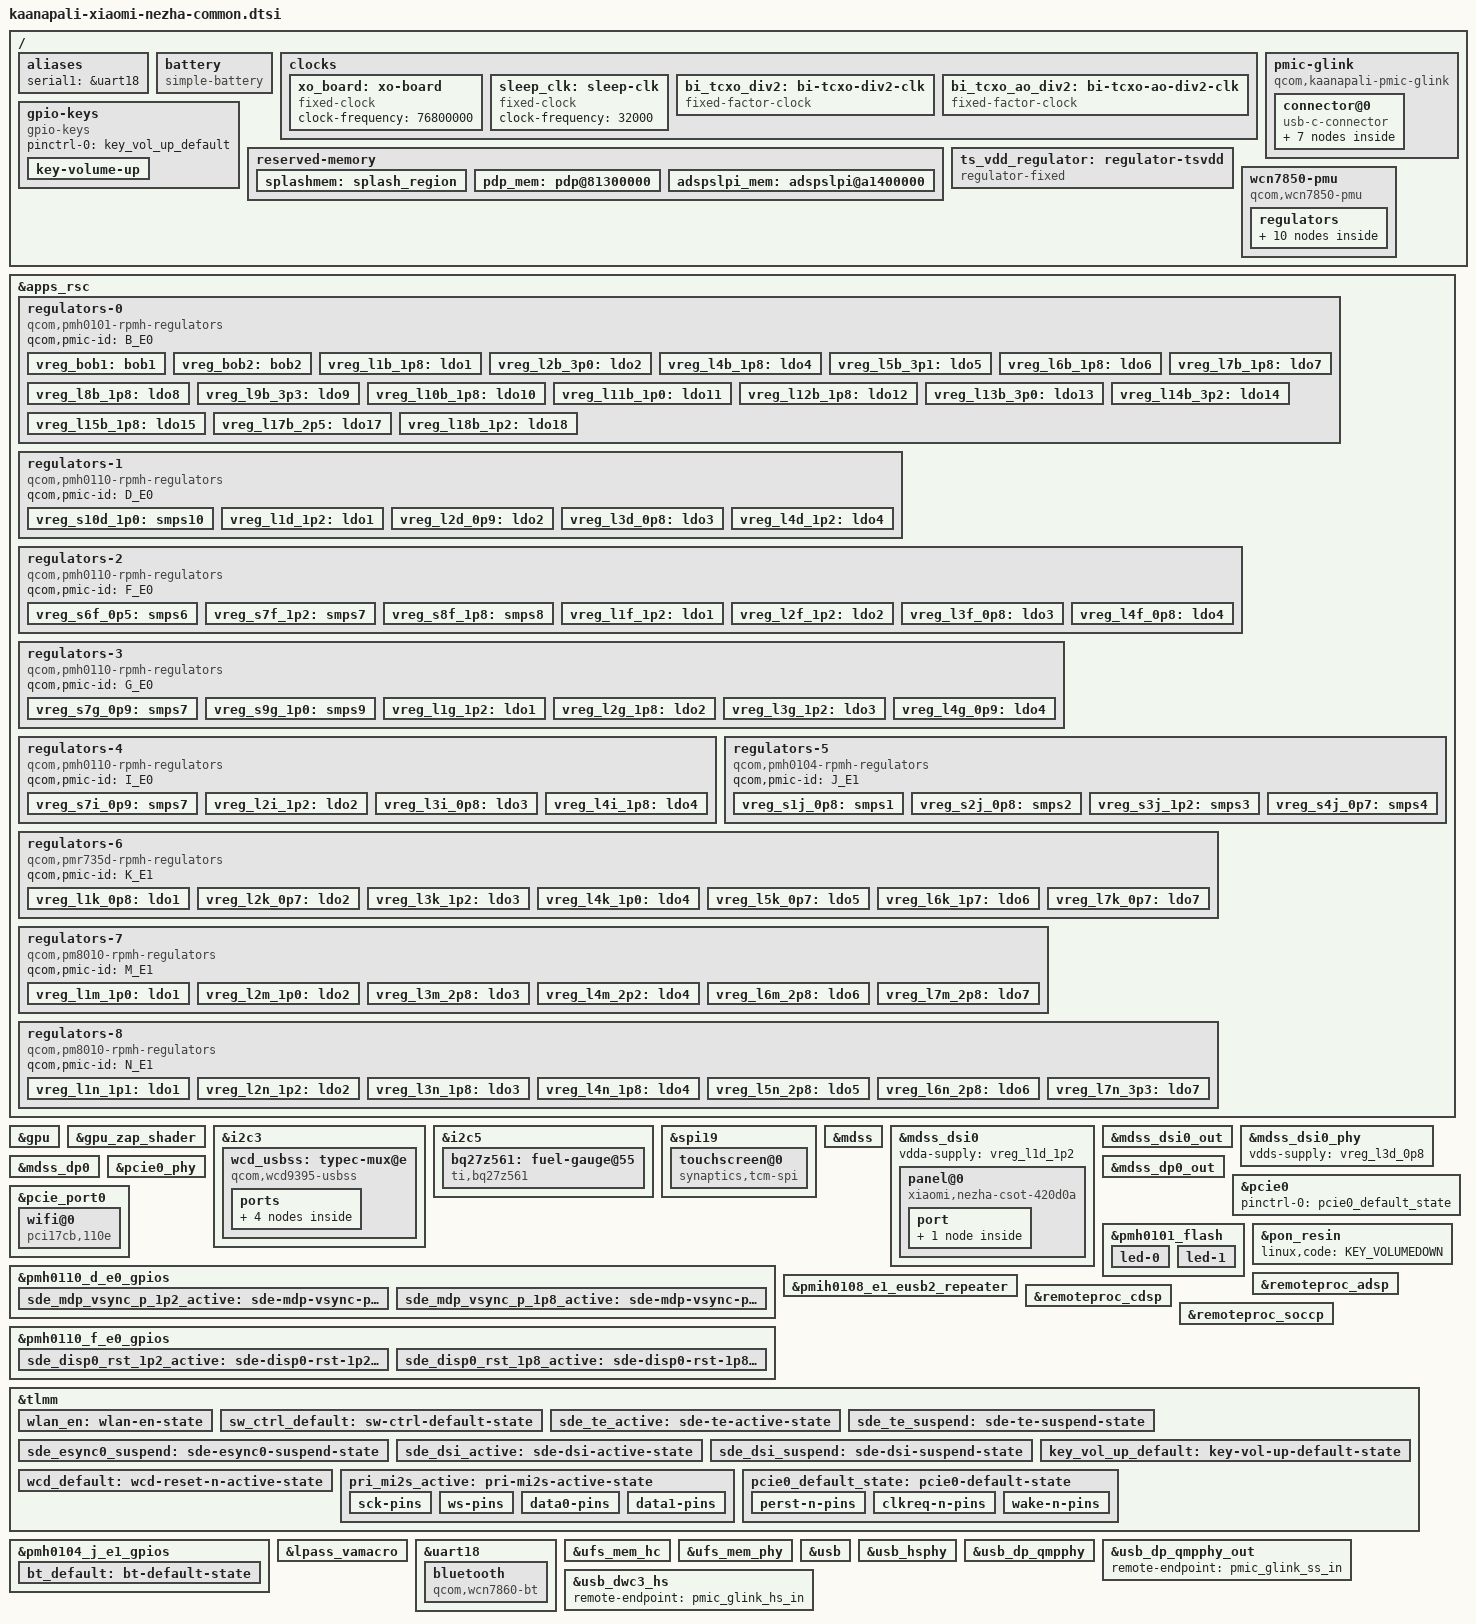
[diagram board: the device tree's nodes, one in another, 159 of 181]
// SPDX-License-Identifier: BSD-3-Clause
/*
 * Copyright (c) Qualcomm Technologies, Inc. and/or its subsidiaries.
 * Copyright (c) Igor Belwon <igor.belwon@mentallysanemainliners.org>
 */

/dts-v1/;

#include <dt-bindings/gpio/gpio.h>
#include <dt-bindings/input/linux-event-codes.h>
#include <dt-bindings/leds/common.h>
#include <dt-bindings/regulator/qcom,rpmh-regulator.h>
#include "kaanapali.dtsi"

#include "pm8010-kaanapali.dtsi"     /* SPMI1: SID-12/13   */
#include "pmd8028-kaanapali.dtsi"    /* SPMI1: SID-4       */
#include "pmh0101.dtsi"              /* SPMI0: SID-1       */
#include "pmh0104-kaanapali.dtsi"    /* SPMI1: SID-9       */
#include "pmh0110-kaanapali.dtsi"    /* SPMI0: SID-3/5/6/8 */
#include "pmih0108-kaanapali.dtsi"   /* SPMI1: SID-7       */
#include "pmk8850.dtsi"              /* SPMI0: SID-0       */
#include "pmr735d-kaanapali.dtsi"    /* SPMI1: SID-10      */

/ {
	aliases {
		serial1 = &uart18;
	};

	battery: battery {
		compatible = "simple-battery";
	};

	clocks {
		xo_board: xo-board {
			compatible = "fixed-clock";
			clock-frequency = <76800000>;
			#clock-cells = <0>;
		};

		sleep_clk: sleep-clk {
			compatible = "fixed-clock";
			clock-frequency = <32000>;
			#clock-cells = <0>;
		};

		bi_tcxo_div2: bi-tcxo-div2-clk {
			compatible = "fixed-factor-clock";
			#clock-cells = <0>;

			clocks = <&rpmhcc RPMH_CXO_CLK>;
			clock-mult = <1>;
			clock-div = <2>;
		};

		bi_tcxo_ao_div2: bi-tcxo-ao-div2-clk {
			compatible = "fixed-factor-clock";
			#clock-cells = <0>;

			clocks = <&rpmhcc RPMH_CXO_CLK_A>;
			clock-mult = <1>;
			clock-div = <2>;
		};
	};

	gpio-keys {
		compatible = "gpio-keys";

		pinctrl-0 = <&key_vol_up_default>;
		pinctrl-names = "default";

		key-volume-up {
			label = "Volume Up";
			linux,code = <KEY_VOLUMEUP>;
			gpios = <&tlmm 101 GPIO_ACTIVE_LOW>;
			debounce-interval = <15>;
			linux,can-disable;
			wakeup-source;
		};
	};

	pmic-glink {
		compatible = "qcom,kaanapali-pmic-glink",
			     "qcom,pmic-glink";
		#address-cells = <1>;
		#size-cells = <0>;

		connector@0 {
			compatible = "usb-c-connector";
			reg = <0>;

			power-role = "dual";
			data-role = "dual";

			ports {
				#address-cells = <1>;
				#size-cells = <0>;

				port@0 {
					reg = <0>;

					pmic_glink_hs_in: endpoint {
						remote-endpoint = <&usb_dwc3_hs>;
					};
				};

				port@1 {
					reg = <1>;

					pmic_glink_ss_in: endpoint {
						remote-endpoint = <&usb_dp_qmpphy_out>;
					};
				};

				port@2 {
					reg = <2>;

					pmic_glink_sbu: endpoint {
						remote-endpoint = <&wcd_usbss_sbu_mux>;
					};
				};
			};
		};
	};

	reserved-memory {
		/*
		 * If we do not have this exact region with this exact name
		 * present, the bootloader disables the display panel and
		 * for some reason it cannot be re-enabled.
		 */
		splashmem: splash_region {
			reg = <0x0 0xfc800000 0x0 0x2b00000>;
			no-map;
		};

		/delete-node/ pdp@81300000;
		pdp_mem: pdp@81300000 {
			reg = <0x0 0x81200000 0x0 0x200000>;
			no-map;
		};

		/delete-node/ adspslpi@a1400000;
		adspslpi_mem: adspslpi@a1400000 {
			reg = <0x0 0xa1400000 0x0 0x5580000>;
			no-map;
		};
	};

	ts_vdd_regulator: regulator-tsvdd {
		compatible = "regulator-fixed";
		regulator-name = "ts_vdd";
		regulator-min-microvolt = <3000000>;
		regulator-max-microvolt = <3000000>;

		gpio = <&tlmm 215 GPIO_ACTIVE_HIGH>;
		enable-active-high;
	};

	wcn7850-pmu {
		compatible = "qcom,wcn7850-pmu";

		pinctrl-0 = <&bt_default>, <&sw_ctrl_default>, <&wlan_en>;
		pinctrl-names = "default";

		bt-enable-gpios = <&pmh0104_j_e1_gpios 5 GPIO_ACTIVE_HIGH>;
		wlan-enable-gpios = <&tlmm 16 GPIO_ACTIVE_HIGH>;

		vdd-supply = <&vreg_s2j_0p8>;
		vddio-supply = <&vreg_l2g_1p8>;
		vddio1p2-supply = <&vreg_l3g_1p2>;
		vddaon-supply = <&vreg_s7g_0p9>;
		vdddig-supply = <&vreg_s1j_0p8>;
		vddrfa1p2-supply = <&vreg_s7f_1p2>;
		vddrfa1p8-supply = <&vreg_s8f_1p8>;

		clocks = <&rpmhcc RPMH_RF_CLK1>;

		regulators {
			vreg_pmu_rfa_cmn: ldo0 {
				regulator-name = "vreg_pmu_rfa_cmn";
			};

			vreg_pmu_aon_0p59: ldo1 {
				regulator-name = "vreg_pmu_aon_0p59";
			};

			vreg_pmu_wlcx_0p8: ldo2 {
				regulator-name = "vreg_pmu_wlcx_0p8";
			};

			vreg_pmu_wlmx_0p85: ldo3 {
				regulator-name = "vreg_pmu_wlmx_0p85";
			};

			vreg_pmu_btcmx_0p85: ldo4 {
				regulator-name = "vreg_pmu_btcmx_0p85";
			};

			vreg_pmu_rfa_0p8: ldo5 {
				regulator-name = "vreg_pmu_rfa_0p8";
			};

			vreg_pmu_rfa_1p2: ldo6 {
				regulator-name = "vreg_pmu_rfa_1p2";
			};

			vreg_pmu_rfa_1p8: ldo7 {
				regulator-name = "vreg_pmu_rfa_1p8";
			};

			vreg_pmu_pcie_0p9: ldo8 {
				regulator-name = "vreg_pmu_pcie_0p9";
			};

			vreg_pmu_pcie_1p8: ldo9 {
				regulator-name = "vreg_pmu_pcie_1p8";
			};
		};
	};
};

&apps_rsc {
	regulators-0 {
		compatible = "qcom,pmh0101-rpmh-regulators";
		qcom,pmic-id = "B_E0";

		vreg_bob1: bob1 {
			regulator-name = "vreg_bob1";
			regulator-min-microvolt = <3008000>;
			regulator-max-microvolt = <4000000>;
			regulator-initial-mode = <RPMH_REGULATOR_MODE_HPM>;
		};

		vreg_bob2: bob2 {
			regulator-name = "vreg_bob2";
			regulator-min-microvolt = <2704000>;
			regulator-max-microvolt = <3552000>;
			regulator-initial-mode = <RPMH_REGULATOR_MODE_HPM>;
		};

		vreg_l1b_1p8: ldo1 {
			regulator-name = "vreg_l1b_1p8";
			regulator-min-microvolt = <1800000>;
			regulator-max-microvolt = <1800000>;
			regulator-initial-mode = <RPMH_REGULATOR_MODE_AUTO>;
			regulator-allow-set-load;
			regulator-allowed-modes = <RPMH_REGULATOR_MODE_LPM
						   RPMH_REGULATOR_MODE_AUTO>;
		};

		vreg_l2b_3p0: ldo2 {
			regulator-name = "vreg_l2b_3p0";
			regulator-min-microvolt = <3008000>;
			regulator-max-microvolt = <3048000>;
			regulator-initial-mode = <RPMH_REGULATOR_MODE_AUTO>;
			regulator-allow-set-load;
			regulator-allowed-modes = <RPMH_REGULATOR_MODE_LPM
						   RPMH_REGULATOR_MODE_AUTO>;
		};

		vreg_l4b_1p8: ldo4 {
			regulator-name = "vreg_l4b_1p8";
			regulator-min-microvolt = <1800000>;
			regulator-max-microvolt = <1800000>;
			regulator-initial-mode = <RPMH_REGULATOR_MODE_AUTO>;
			regulator-allow-set-load;
			regulator-allowed-modes = <RPMH_REGULATOR_MODE_LPM
						   RPMH_REGULATOR_MODE_AUTO>;
		};

		vreg_l5b_3p1: ldo5 {
			regulator-name = "vreg_l5b_3p1";
			regulator-min-microvolt = <3100000>;
			regulator-max-microvolt = <3148000>;
			regulator-initial-mode = <RPMH_REGULATOR_MODE_AUTO>;
			regulator-allow-set-load;
			regulator-allowed-modes = <RPMH_REGULATOR_MODE_LPM
						   RPMH_REGULATOR_MODE_AUTO>;
		};

		vreg_l6b_1p8: ldo6 {
			regulator-name = "vreg_l6b_1p8";
			regulator-min-microvolt = <1800000>;
			regulator-max-microvolt = <3008000>;
			regulator-initial-mode = <RPMH_REGULATOR_MODE_AUTO>;
			regulator-allow-set-load;
			regulator-allowed-modes = <RPMH_REGULATOR_MODE_LPM
						   RPMH_REGULATOR_MODE_AUTO>;
		};

		vreg_l7b_1p8: ldo7 {
			regulator-name = "vreg_l7b_1p8";
			regulator-min-microvolt = <1800000>;
			regulator-max-microvolt = <3008000>;
			regulator-initial-mode = <RPMH_REGULATOR_MODE_AUTO>;
			regulator-allow-set-load;
			regulator-allowed-modes = <RPMH_REGULATOR_MODE_LPM
						   RPMH_REGULATOR_MODE_AUTO>;
		};

		vreg_l8b_1p8: ldo8 {
			regulator-name = "vreg_l8b_1p8";
			regulator-min-microvolt = <1800000>;
			regulator-max-microvolt = <3008000>;
			regulator-initial-mode = <RPMH_REGULATOR_MODE_AUTO>;
			regulator-allow-set-load;
			regulator-allowed-modes = <RPMH_REGULATOR_MODE_LPM
						   RPMH_REGULATOR_MODE_AUTO>;
		};

		vreg_l9b_3p3: ldo9 {
			regulator-name = "vreg_l9b_2p9";
			regulator-min-microvolt = <3008000>;
			regulator-max-microvolt = <3300000>;
			regulator-initial-mode = <RPMH_REGULATOR_MODE_HPM>;
			regulator-allow-set-load;
			regulator-allowed-modes = <RPMH_REGULATOR_MODE_LPM
						   RPMH_REGULATOR_MODE_HPM>;
		};

		vreg_l10b_1p8: ldo10 {
			regulator-name = "vreg_l10b_1p8";
			regulator-min-microvolt = <1800000>;
			regulator-max-microvolt = <1800000>;
			regulator-initial-mode = <RPMH_REGULATOR_MODE_AUTO>;
			regulator-allow-set-load;
			regulator-allowed-modes = <RPMH_REGULATOR_MODE_LPM
						   RPMH_REGULATOR_MODE_AUTO>;
		};

		vreg_l11b_1p0: ldo11 {
			regulator-name = "vreg_l11b_1p0";
			regulator-min-microvolt = <1000000>;
			regulator-max-microvolt = <1292000>;
			regulator-initial-mode = <RPMH_REGULATOR_MODE_AUTO>;
			regulator-allow-set-load;
			regulator-allowed-modes = <RPMH_REGULATOR_MODE_LPM
						   RPMH_REGULATOR_MODE_AUTO>;
		};

		vreg_l12b_1p8: ldo12 {
			regulator-name = "vreg_l12b_1p8";
			regulator-min-microvolt = <1200000>;
			regulator-max-microvolt = <1800000>;
			regulator-initial-mode = <RPMH_REGULATOR_MODE_AUTO>;
			regulator-allow-set-load;
			regulator-allowed-modes = <RPMH_REGULATOR_MODE_LPM
						   RPMH_REGULATOR_MODE_AUTO>;
		};

		vreg_l13b_3p0: ldo13 {
			regulator-name = "vreg_l13b_3p0";
			regulator-min-microvolt = <3000000>;
			regulator-max-microvolt = <3000000>;
			regulator-initial-mode = <RPMH_REGULATOR_MODE_AUTO>;
			regulator-allow-set-load;
			regulator-allowed-modes = <RPMH_REGULATOR_MODE_LPM
						   RPMH_REGULATOR_MODE_AUTO>;
		};

		vreg_l14b_3p2: ldo14 {
			regulator-name = "vreg_l14b_3p2";
			regulator-min-microvolt = <3200000>;
			regulator-max-microvolt = <3200000>;
			regulator-initial-mode = <RPMH_REGULATOR_MODE_AUTO>;
			regulator-allow-set-load;
			regulator-allowed-modes = <RPMH_REGULATOR_MODE_LPM
						   RPMH_REGULATOR_MODE_AUTO>;
		};

		vreg_l15b_1p8: ldo15 {
			regulator-name = "vreg_l15b_1p8";
			regulator-min-microvolt = <1800000>;
			regulator-max-microvolt = <1800000>;
			regulator-initial-mode = <RPMH_REGULATOR_MODE_AUTO>;
			regulator-allow-set-load;
			regulator-allowed-modes = <RPMH_REGULATOR_MODE_LPM
						   RPMH_REGULATOR_MODE_AUTO>;
		};

		/* L16B: 3.3v */

		vreg_l17b_2p5: ldo17 {
			regulator-name = "vreg_l17b_2p5";
			regulator-min-microvolt = <2504000>;
			regulator-max-microvolt = <2504000>;
			regulator-initial-mode = <RPMH_REGULATOR_MODE_HPM>;
			regulator-allow-set-load;
			regulator-allowed-modes = <RPMH_REGULATOR_MODE_LPM
						   RPMH_REGULATOR_MODE_HPM>;
		};

		vreg_l18b_1p2: ldo18 {
			regulator-name = "vreg_l18b_1p2";
			regulator-min-microvolt = <1200000>;
			regulator-max-microvolt = <1200000>;
			regulator-initial-mode = <RPMH_REGULATOR_MODE_AUTO>;
			regulator-allow-set-load;
			regulator-allowed-modes = <RPMH_REGULATOR_MODE_LPM
						   RPMH_REGULATOR_MODE_AUTO>;
		};
	};

	regulators-1 {
		compatible = "qcom,pmh0110-rpmh-regulators";
		qcom,pmic-id = "D_E0";

		vreg_s10d_1p0: smps10 {
			regulator-name = "vreg_s10d_1p0";
			regulator-min-microvolt = <1000000>;
			regulator-max-microvolt = <1100000>;
			regulator-initial-mode = <RPMH_REGULATOR_MODE_HPM>;
		};

		vreg_l1d_1p2: ldo1 {
			regulator-name = "vreg_l1d_1p2";
			regulator-min-microvolt = <1200000>;
			regulator-max-microvolt = <1256000>;
			regulator-initial-mode = <RPMH_REGULATOR_MODE_AUTO>;
			regulator-allow-set-load;
			regulator-allowed-modes = <RPMH_REGULATOR_MODE_LPM
						   RPMH_REGULATOR_MODE_AUTO>;
		};

		vreg_l2d_0p9: ldo2 {
			regulator-name = "vreg_l2d_0p9";
			regulator-min-microvolt = <912000>;
			regulator-max-microvolt = <958000>;
			regulator-initial-mode = <RPMH_REGULATOR_MODE_AUTO>;
			regulator-allow-set-load;
			regulator-allowed-modes = <RPMH_REGULATOR_MODE_LPM
						   RPMH_REGULATOR_MODE_AUTO>;
		};

		vreg_l3d_0p8: ldo3 {
			regulator-name = "vreg_l3d_0p8";
			regulator-min-microvolt = <880000>;
			regulator-max-microvolt = <880000>;
			regulator-initial-mode = <RPMH_REGULATOR_MODE_AUTO>;
			regulator-allow-set-load;
			regulator-allowed-modes = <RPMH_REGULATOR_MODE_LPM
						   RPMH_REGULATOR_MODE_AUTO>;
		};

		vreg_l4d_1p2: ldo4 {
			regulator-name = "vreg_l4d_1p2";
			regulator-min-microvolt = <1200000>;
			regulator-max-microvolt = <1200000>;
			regulator-initial-mode = <RPMH_REGULATOR_MODE_AUTO>;
			regulator-allow-set-load;
			regulator-allowed-modes = <RPMH_REGULATOR_MODE_LPM
						   RPMH_REGULATOR_MODE_AUTO>;
		};
	};

	regulators-2 {
		compatible = "qcom,pmh0110-rpmh-regulators";
		qcom,pmic-id = "F_E0";

		vreg_s6f_0p5: smps6 {
			regulator-name = "vreg_s6f_0p5";
			regulator-min-microvolt = <300000>;
			regulator-max-microvolt = <570000>;
			regulator-initial-mode = <RPMH_REGULATOR_MODE_HPM>;
		};

		vreg_s7f_1p2: smps7 {
			regulator-name = "vreg_s7f_1p2";
			regulator-min-microvolt = <1224000>;
			regulator-max-microvolt = <1372000>;
			regulator-initial-mode = <RPMH_REGULATOR_MODE_HPM>;
		};

		vreg_s8f_1p8: smps8 {
			regulator-name = "vreg_s8f_1p8";
			regulator-min-microvolt = <1800000>;
			regulator-max-microvolt = <2000000>;
			regulator-initial-mode = <RPMH_REGULATOR_MODE_HPM>;
		};

		vreg_l1f_1p2: ldo1 {
			regulator-name = "vreg_l1f_1p2";
			regulator-min-microvolt = <1200000>;
			regulator-max-microvolt = <1200000>;
			regulator-initial-mode = <RPMH_REGULATOR_MODE_AUTO>;
			regulator-allow-set-load;
			regulator-allowed-modes = <RPMH_REGULATOR_MODE_LPM
						   RPMH_REGULATOR_MODE_AUTO>;
		};

		vreg_l2f_1p2: ldo2 {
			regulator-name = "vreg_l2f_1p2";
			regulator-min-microvolt = <1200000>;
			regulator-max-microvolt = <1200000>;
			regulator-initial-mode = <RPMH_REGULATOR_MODE_AUTO>;
			regulator-allow-set-load;
			regulator-allowed-modes = <RPMH_REGULATOR_MODE_LPM
						   RPMH_REGULATOR_MODE_AUTO>;
		};

		vreg_l3f_0p8: ldo3 {
			regulator-name = "vreg_l3f_0p8";
			regulator-min-microvolt = <880000>;
			regulator-max-microvolt = <936000>;
			regulator-initial-mode = <RPMH_REGULATOR_MODE_AUTO>;
			regulator-allow-set-load;
			regulator-allowed-modes = <RPMH_REGULATOR_MODE_LPM
						   RPMH_REGULATOR_MODE_AUTO>;
		};

		vreg_l4f_0p8: ldo4 {
			regulator-name = "vreg_l4f_0p8";
			regulator-min-microvolt = <880000>;
			regulator-max-microvolt = <912000>;
			regulator-initial-mode = <RPMH_REGULATOR_MODE_AUTO>;
			regulator-allow-set-load;
			regulator-allowed-modes = <RPMH_REGULATOR_MODE_LPM
						   RPMH_REGULATOR_MODE_AUTO>;
		};
	};

	regulators-3 {
		compatible = "qcom,pmh0110-rpmh-regulators";
		qcom,pmic-id = "G_E0";

		vreg_s7g_0p9: smps7 {
			regulator-name = "vreg_s7g_0p9";
			regulator-min-microvolt = <880000>;
			regulator-max-microvolt = <1100000>;
			regulator-initial-mode = <RPMH_REGULATOR_MODE_HPM>;
		};

		vreg_s9g_1p0: smps9 {
			regulator-name = "vreg_s9g_1p0";
			regulator-min-microvolt = <1000000>;
			regulator-max-microvolt = <1100000>;
			regulator-initial-mode = <RPMH_REGULATOR_MODE_HPM>;
		};

		vreg_l1g_1p2: ldo1 {
			regulator-name = "vreg_l1g_1p2";
			regulator-min-microvolt = <1200000>;
			regulator-max-microvolt = <1200000>;
			regulator-initial-mode = <RPMH_REGULATOR_MODE_AUTO>;
			regulator-allow-set-load;
			regulator-allowed-modes = <RPMH_REGULATOR_MODE_LPM
						   RPMH_REGULATOR_MODE_AUTO>;
		};

		vreg_l2g_1p8: ldo2 {
			regulator-name = "vreg_l2g_1p8";
			regulator-min-microvolt = <1800000>;
			regulator-max-microvolt = <1800000>;
			regulator-initial-mode = <RPMH_REGULATOR_MODE_AUTO>;
			regulator-allow-set-load;
			regulator-allowed-modes = <RPMH_REGULATOR_MODE_LPM
						   RPMH_REGULATOR_MODE_AUTO>;
		};

		vreg_l3g_1p2: ldo3 {
			regulator-name = "vreg_l3g_1p2";
			regulator-min-microvolt = <1200000>;
			regulator-max-microvolt = <1200000>;
			regulator-initial-mode = <RPMH_REGULATOR_MODE_AUTO>;
			regulator-allow-set-load;
			regulator-allowed-modes = <RPMH_REGULATOR_MODE_LPM
						   RPMH_REGULATOR_MODE_AUTO>;
		};

		vreg_l4g_0p9: ldo4 {
			regulator-name = "vreg_l4g_0p9";
			regulator-min-microvolt = <880000>;
			regulator-max-microvolt = <920000>;
			regulator-initial-mode = <RPMH_REGULATOR_MODE_AUTO>;
			regulator-allow-set-load;
			regulator-allowed-modes = <RPMH_REGULATOR_MODE_LPM
						   RPMH_REGULATOR_MODE_AUTO>;
		};
	};

	regulators-4 {
		compatible = "qcom,pmh0110-rpmh-regulators";
		qcom,pmic-id = "I_E0";

		vreg_s7i_0p9: smps7 {
			regulator-name = "vreg_s7i_0p9";
			regulator-min-microvolt = <900000>;
			regulator-max-microvolt = <972000>;
			regulator-initial-mode = <RPMH_REGULATOR_MODE_HPM>;
		};

		vreg_l2i_1p2: ldo2 {
			regulator-name = "vreg_l2i_1p2";
			regulator-min-microvolt = <1200000>;
			regulator-max-microvolt = <1200000>;
			regulator-initial-mode = <RPMH_REGULATOR_MODE_AUTO>;
			regulator-allow-set-load;
			regulator-allowed-modes = <RPMH_REGULATOR_MODE_LPM
						   RPMH_REGULATOR_MODE_AUTO>;
		};

		vreg_l3i_0p8: ldo3 {
			regulator-name = "vreg_l3i_0p8";
			regulator-min-microvolt = <880000>;
			regulator-max-microvolt = <920000>;
			regulator-initial-mode = <RPMH_REGULATOR_MODE_AUTO>;
			regulator-allow-set-load;
			regulator-allowed-modes = <RPMH_REGULATOR_MODE_LPM
						   RPMH_REGULATOR_MODE_AUTO>;
		};

		vreg_l4i_1p8: ldo4 {
			regulator-name = "vreg_l4i_1p8";
			regulator-min-microvolt = <1800000>;
			regulator-max-microvolt = <1800000>;
			regulator-initial-mode = <RPMH_REGULATOR_MODE_AUTO>;
			regulator-allow-set-load;
			regulator-allowed-modes = <RPMH_REGULATOR_MODE_LPM
			RPMH_REGULATOR_MODE_AUTO>;
		};
	};

	regulators-5 {
		compatible = "qcom,pmh0104-rpmh-regulators";
		qcom,pmic-id = "J_E1";

		vreg_s1j_0p8: smps1 {
			regulator-name = "vreg_s1j_0p8";
			regulator-min-microvolt = <400000>;
			regulator-max-microvolt = <1000000>;
			regulator-initial-mode = <RPMH_REGULATOR_MODE_HPM>;
		};

		vreg_s2j_0p8: smps2 {
			regulator-name = "vreg_s2j_0p8";
			regulator-min-microvolt = <500000>;
			regulator-max-microvolt = <1100000>;
			regulator-initial-mode = <RPMH_REGULATOR_MODE_HPM>;
		};

		vreg_s3j_1p2: smps3 {
			regulator-name = "vreg_s3j_1p2";
			regulator-min-microvolt = <1200000>;
			regulator-max-microvolt = <1300000>;
			regulator-initial-mode = <RPMH_REGULATOR_MODE_HPM>;
		};

		vreg_s4j_0p7: smps4 {
			regulator-name = "vreg_s4j_0p7";
			regulator-min-microvolt = <300000>;
			regulator-max-microvolt = <1000000>;
			regulator-initial-mode = <RPMH_REGULATOR_MODE_HPM>;
		};
	};

	regulators-6 {
		compatible = "qcom,pmr735d-rpmh-regulators";
		qcom,pmic-id = "K_E1";

		vreg_l1k_0p8: ldo1 {
			regulator-name = "vreg_l1k_0p8";
			regulator-min-microvolt = <300000>;
			regulator-max-microvolt = <1100000>;
			regulator-initial-mode = <RPMH_REGULATOR_MODE_HPM>;
			regulator-allow-set-load;
			regulator-allowed-modes = <RPMH_REGULATOR_MODE_LPM
						   RPMH_REGULATOR_MODE_HPM>;
		};

		vreg_l2k_0p7: ldo2 {
			regulator-name = "vreg_l2k_0p7";
			regulator-min-microvolt = <700000>;
			regulator-max-microvolt = <1000000>;
			regulator-initial-mode = <RPMH_REGULATOR_MODE_HPM>;
			regulator-allow-set-load;
			regulator-allowed-modes = <RPMH_REGULATOR_MODE_LPM
						   RPMH_REGULATOR_MODE_HPM>;
		};

		vreg_l3k_1p2: ldo3 {
			regulator-name = "vreg_l3k_1p2";
			regulator-min-microvolt = <1200000>;
			regulator-max-microvolt = <1200000>;
			regulator-initial-mode = <RPMH_REGULATOR_MODE_HPM>;
			regulator-allow-set-load;
			regulator-allowed-modes = <RPMH_REGULATOR_MODE_LPM
						   RPMH_REGULATOR_MODE_HPM>;
		};

		vreg_l4k_1p0: ldo4 {
			regulator-name = "vreg_l4k_1p0";
			regulator-min-microvolt = <1000000>;
			regulator-max-microvolt = <1200000>;
			regulator-initial-mode = <RPMH_REGULATOR_MODE_HPM>;
			regulator-allow-set-load;
			regulator-allowed-modes = <RPMH_REGULATOR_MODE_LPM
						   RPMH_REGULATOR_MODE_HPM>;
		};

		vreg_l5k_0p7: ldo5 {
			regulator-name = "vreg_l5k_0p7";
			regulator-min-microvolt = <700000>;
			regulator-max-microvolt = <1000000>;
			regulator-initial-mode = <RPMH_REGULATOR_MODE_HPM>;
			regulator-allow-set-load;
			regulator-allowed-modes = <RPMH_REGULATOR_MODE_LPM
						   RPMH_REGULATOR_MODE_HPM>;
		};

		vreg_l6k_1p7: ldo6 {
			regulator-name = "vreg_l6k_1p7";
			regulator-min-microvolt = <1700000>;
			regulator-max-microvolt = <2000000>;
			regulator-initial-mode = <RPMH_REGULATOR_MODE_HPM>;
			regulator-allow-set-load;
			regulator-allowed-modes = <RPMH_REGULATOR_MODE_LPM
						   RPMH_REGULATOR_MODE_HPM>;
		};

		vreg_l7k_0p7: ldo7 {
			regulator-name = "vreg_l7k_0p7";
			regulator-min-microvolt = <700000>;
			regulator-max-microvolt = <848000>;
			regulator-initial-mode = <RPMH_REGULATOR_MODE_HPM>;
			regulator-allow-set-load;
			regulator-allowed-modes = <RPMH_REGULATOR_MODE_LPM
						   RPMH_REGULATOR_MODE_HPM>;
		};
	};

	regulators-7 {
		compatible = "qcom,pm8010-rpmh-regulators";
		qcom,pmic-id = "M_E1";

		vreg_l1m_1p0: ldo1 {
			regulator-name = "vreg_l1m_1p0";
			regulator-min-microvolt = <1000000>;
			regulator-max-microvolt = <1100000>;
			regulator-initial-mode = <RPMH_REGULATOR_MODE_HPM>;
			regulator-allow-set-load;
			regulator-allowed-modes = <RPMH_REGULATOR_MODE_LPM
						   RPMH_REGULATOR_MODE_HPM>;
		};

		vreg_l2m_1p0: ldo2 {
			regulator-name = "vreg_l2m_1p0";
			regulator-min-microvolt = <1096000>;
			regulator-max-microvolt = <1104000>;
			regulator-initial-mode = <RPMH_REGULATOR_MODE_HPM>;
			regulator-allow-set-load;
			regulator-allowed-modes = <RPMH_REGULATOR_MODE_LPM
						   RPMH_REGULATOR_MODE_HPM>;
		};

		vreg_l3m_2p8: ldo3 {
			regulator-name = "vreg_l3m_2p8";
			regulator-min-microvolt = <2800000>;
			regulator-max-microvolt = <2900000>;
			regulator-initial-mode = <RPMH_REGULATOR_MODE_HPM>;
		};

		vreg_l4m_2p2: ldo4 {
			regulator-name = "vreg_l4m_2p2";
			regulator-min-microvolt = <2200000>;
			regulator-max-microvolt = <2200000>;
			regulator-initial-mode = <RPMH_REGULATOR_MODE_HPM>;
		};

		vreg_l6m_2p8: ldo6 {
			regulator-name = "vreg_l6m_2p8";
			regulator-min-microvolt = <2800000>;
			regulator-max-microvolt = <2800000>;
			regulator-initial-mode = <RPMH_REGULATOR_MODE_HPM>;
		};

		vreg_l7m_2p8: ldo7 {
			regulator-name = "vreg_l7m_2p8";
			regulator-min-microvolt = <2800000>;
			regulator-max-microvolt = <2800000>;
			regulator-initial-mode = <RPMH_REGULATOR_MODE_HPM>;
		};
	};

	regulators-8 {
		compatible = "qcom,pm8010-rpmh-regulators";
		qcom,pmic-id = "N_E1";

		vreg_l1n_1p1: ldo1 {
			regulator-name = "vreg_l1n_1p1";
			regulator-min-microvolt = <1096000>;
			regulator-max-microvolt = <1104000>;
			regulator-initial-mode = <RPMH_REGULATOR_MODE_HPM>;
			regulator-allow-set-load;
			regulator-allowed-modes = <RPMH_REGULATOR_MODE_LPM
						   RPMH_REGULATOR_MODE_HPM>;
		};

		vreg_l2n_1p2: ldo2 {
			regulator-name = "vreg_l2n_1p2";
			regulator-min-microvolt = <1200000>;
			regulator-max-microvolt = <1200000>;
			regulator-initial-mode = <RPMH_REGULATOR_MODE_HPM>;
			regulator-allow-set-load;
			regulator-allowed-modes = <RPMH_REGULATOR_MODE_LPM
						   RPMH_REGULATOR_MODE_HPM>;
		};

		vreg_l3n_1p8: ldo3 {
			regulator-name = "vreg_l3n_1p8";
			regulator-min-microvolt = <1800000>;
			regulator-max-microvolt = <1800000>;
			regulator-initial-mode = <RPMH_REGULATOR_MODE_HPM>;
		};

		vreg_l4n_1p8: ldo4 {
			regulator-name = "vreg_l4n_1p8";
			regulator-min-microvolt = <1800000>;
			regulator-max-microvolt = <1800000>;
			regulator-initial-mode = <RPMH_REGULATOR_MODE_HPM>;
		};

		vreg_l5n_2p8: ldo5 {
			regulator-name = "vreg_l5n_2p8";
			regulator-min-microvolt = <2800000>;
			regulator-max-microvolt = <2800000>;
			regulator-initial-mode = <RPMH_REGULATOR_MODE_HPM>;
		};

		vreg_l6n_2p8: ldo6 {
			regulator-name = "vreg_l6n_2p8";
			regulator-min-microvolt = <2800000>;
			regulator-max-microvolt = <2800000>;
			regulator-initial-mode = <RPMH_REGULATOR_MODE_HPM>;
		};

		vreg_l7n_3p3: ldo7 {
			regulator-name = "vreg_l7n_3p3";
			regulator-min-microvolt = <3304000>;
			regulator-max-microvolt = <3304000>;
			regulator-initial-mode = <RPMH_REGULATOR_MODE_HPM>;
		};
	};
};

&gpu {
	status = "okay";
};

&gpu_zap_shader {
	firmware-name = "qcom/kaanapali/xiaomi/nezha/gen80200_zap.mbn";
};

&i2c3 {
	status = "okay";

	wcd_usbss: typec-mux@e {
		compatible = "qcom,wcd9395-usbss", "qcom,wcd9390-usbss";
		reg = <0xe>;

		vdd-supply = <&vreg_l15b_1p8>;
		reset-gpios = <&tlmm 162 GPIO_ACTIVE_HIGH>;

		mode-switch;
		orientation-switch;

		ports {
			#address-cells = <1>;
			#size-cells = <0>;

			port@0 {
				reg = <0>;

				wcd_usbss_sbu_mux: endpoint {
					remote-endpoint = <&pmic_glink_sbu>;
				};
			};

			port@1 {
				reg = <1>;

				wcd_usbss_headset_out: endpoint {
					//remote-endpoint = <&wcd_codec_headset_in>;
				};
			};
		};
	};
};

&i2c5 {
	status = "okay";

	bq27z561: fuel-gauge@55 {
		compatible = "ti,bq27z561";
		reg = <0x55>;
		monitored-battery = <&battery>;
	};
};

&spi19 {
	status = "okay";

	touchscreen@0 {
		compatible = "synaptics,tcm-spi";
		reg = <0>;
		spi-max-frequency = <15000000>;

		interrupt-parent = <&tlmm>;
		interrupts = <158 IRQ_TYPE_LEVEL_LOW>;

		reset-gpios = <&tlmm 66 GPIO_ACTIVE_LOW>;

		vdd-supply = <&ts_vdd_regulator>;
		avdd-supply = <&vreg_l4i_1p8>;

		status = "okay";
	};
};

&mdss {
	status = "okay";
};

&mdss_dsi0 {
	vdda-supply = <&vreg_l1d_1p2>;
	status = "okay";

	panel@0 {
		compatible = "xiaomi,nezha-csot-420d0a";
		reg = <0>;

		pinctrl-0 = <&sde_dsi_active &sde_te_active &sde_esync0_suspend
			     &sde_mdp_vsync_p_1p2_active &sde_mdp_vsync_p_1p8_active
			     &sde_disp0_rst_1p2_active &sde_disp0_rst_1p8_active>;
		pinctrl-1 = <&sde_dsi_suspend &sde_te_suspend &sde_esync0_suspend
			     &sde_mdp_vsync_p_1p2_active &sde_mdp_vsync_p_1p8_active
			     &sde_disp0_rst_1p2_active &sde_disp0_rst_1p8_active>;
		pinctrl-names = "default", "sleep";

		vci-supply = <&vreg_l13b_3p0>;
		vdd-supply = <&vreg_l11b_1p0>;
		vddio-supply = <&vreg_l12b_1p8>;

		reset-gpios = <&tlmm 98 GPIO_ACTIVE_LOW>;

		port {
			panel0_in: endpoint {
				remote-endpoint = <&mdss_dsi0_out>;
			};
		};
	};
};

&mdss_dsi0_out {
	remote-endpoint = <&panel0_in>;
	data-lanes = <0 1 2 3>;

	status = "okay";
};

&mdss_dsi0_phy {
	vdds-supply = <&vreg_l3d_0p8>;

	status = "okay";
};

&mdss_dp0 {
	status = "okay";
};

&mdss_dp0_out {
	link-frequencies = /bits/ 64 <1620000000 2700000000 5400000000 8100000000>;
};

&pcie0 {
	pinctrl-0 = <&pcie0_default_state>;
	pinctrl-names = "default";

	status = "okay";
};

&pcie0_phy {
	vdda-phy-supply = <&vreg_l3i_0p8>;
	vdda-pll-supply = <&vreg_l1d_1p2>;

	status = "okay";
};

&pcie_port0 {
	wake-gpios = <&tlmm 104 GPIO_ACTIVE_HIGH>;
	reset-gpios = <&tlmm 102 GPIO_ACTIVE_LOW>;

	wifi@0 {
		compatible = "pci17cb,110e";
		reg = <0x10000 0x0 0x0 0x0 0x0>;

		vddrfacmn-supply = <&vreg_pmu_rfa_cmn>;
		vddaon-supply = <&vreg_pmu_aon_0p59>;
		vddwlcx-supply = <&vreg_pmu_wlcx_0p8>;
		vddwlmx-supply = <&vreg_pmu_wlmx_0p85>;
		vddrfa0p8-supply = <&vreg_pmu_rfa_0p8>;
		vddrfa1p2-supply = <&vreg_pmu_rfa_1p2>;
		vddrfa1p8-supply = <&vreg_pmu_rfa_1p8>;
		vddpcie0p9-supply = <&vreg_pmu_pcie_0p9>;
		vddpcie1p8-supply = <&vreg_pmu_pcie_1p8>;
	};
};

&pmh0110_d_e0_gpios {
	sde_mdp_vsync_p_1p2_active: sde-mdp-vsync-p-1p2-active-state {
		pins = "gpio9";
		function = "paired";
		input-disable;
		output-enable;
		power-source = <2>; /* 1.2v */
	};

	sde_mdp_vsync_p_1p8_active: sde-mdp-vsync-p-1p8-active-state {
		pins = "gpio10";
		function = "paired";
		input-enable;
		output-disable;
		power-source = <1>; /* 1.8v */
	};
};

&pmh0110_f_e0_gpios {
	sde_disp0_rst_1p2_active: sde-disp0-rst-1p2-active-state {
		pins = "gpio9";
		function = "paired";
		input-enable;
		output-disable;
		power-source = <2>; /* 1.2v */
	};

	sde_disp0_rst_1p8_active: sde-disp0-rst-1p8-active-state {
		pins = "gpio10";
		function = "paired";
		input-disable;
		output-enable;
		power-source = <1>; /* 1.8v */
	};
};

&pmh0101_flash {
	status = "okay";

	led-0 {
		function = LED_FUNCTION_FLASH;
		function-enumerator = <0>;
		color = <LED_COLOR_ID_YELLOW>;
		led-sources = <1>, <4>;
		led-max-microamp = <500000>;
		flash-max-microamp = <1200000>;
		flash-max-timeout-us = <300000>;
	};

	led-1 {
		function = LED_FUNCTION_FLASH;
		function-enumerator = <1>;
		color = <LED_COLOR_ID_WHITE>;
		led-sources = <2>, <3>;
		led-max-microamp = <500000>;
		flash-max-microamp = <2000000>;
		flash-max-timeout-us = <1280000>;
	};

	led-1 {
		function = LED_FUNCTION_FLASH;
		function-enumerator = <2>;
		color = <LED_COLOR_ID_AMBER>;
		led-sources = <1>, <2>, <3>, <4>;
		led-max-microamp = <500000>;
		flash-max-microamp = <2000000>;
		flash-max-timeout-us = <1280000>;
	};
};

&pmih0108_e1_eusb2_repeater {
	qcom,tune-usb2-amplitude = /bits/ 8 <0x1>;
	qcom,tune-usb2-disc-thres = /bits/ 8 <0x3>;
	qcom,tune-usb2-preem = /bits/ 8 <0x2>;
	qcom,tune-res-fsdif = /bits/ 8 <0x7>;
	qcom,squelch-detector-bp = <(0)>;

	vdd18-supply = <&vreg_l15b_1p8>;
	vdd3-supply = <&vreg_l5b_3p1>;
};

&pon_resin {
	linux,code = <KEY_VOLUMEDOWN>;

	status = "okay";
};

&remoteproc_adsp {
	firmware-name = "qcom/kaanapali/xiaomi/nezha/adsp.mbn",
			"qcom/kaanapali/xiaomi/nezha/adsp_dtb.mbn";

	status = "okay";
};

&remoteproc_cdsp {
	firmware-name = "qcom/kaanapali/xiaomi/nezha/cdsp.mbn",
			"qcom/kaanapali/xiaomi/nezha/cdsp_dtb.mbn";

	status = "okay";
};

&remoteproc_soccp {
	firmware-name = "qcom/kaanapali/xiaomi/nezha/soccp.mbn",
			"qcom/kaanapali/xiaomi/nezha/soccp_dtb.mbn";
};

&tlmm {
	gpio-reserved-ranges = <28 4>, /* NFC eSE SPI */
			       <36 8>, /* eSE */
			       <74 1>, /* SoCCP */
			       <119 1>,
			       <144 4>; /* CXM UART */

	wlan_en: wlan-en-state {
		pins = "gpio16";
		function = "gpio";
		drive-strength = <8>;
		bias-pull-down;
	};

	sw_ctrl_default: sw-ctrl-default-state {
		pins = "gpio18";
		function = "gpio";
		bias-pull-down;
	};

	sde_te_active: sde-te-active-state {
		pins = "gpio86";
		function = "mdp_vsync";
		drive-strength = <2>;
		bias-pull-down;
	};

	sde_te_suspend: sde-te-suspend-state {
		pins = "gpio86";
		function = "mdp_vsync";
		drive-strength = <2>;
		bias-pull-down;
	};

	sde_esync0_suspend: sde-esync0-suspend-state {
		pins = "gpio88";
		function = "mdp_esync0_out";
		drive-strength = <2>;
		bias-pull-down;
	};

	sde_dsi_active: sde-dsi-active-state {
		pins = "gpio98";
		function = "gpio";
		drive-strength = <8>;
		bias-disable;
	};

	sde_dsi_suspend: sde-dsi-suspend-state {
		pins = "gpio98";
		function = "gpio";
		drive-strength = <2>;
		bias-pull-down;
	};

	key_vol_up_default: key-vol-up-default-state {
		pins = "gpio101";
		function = "gpio";
		output-disable;
		bias-pull-up;
	};

	wcd_default: wcd-reset-n-active-state {
		pins = "gpio161";
		function = "gpio";
		drive-strength = <16>;
		bias-disable;
	};

	pri_mi2s_active: pri-mi2s-active-state {
		sck-pins {
			pins = "gpio122";
			function = "i2s0_sck";
			drive-strength = <8>;
			bias-disable;
		};

		ws-pins {
			pins = "gpio125";
			function = "i2s0_ws";
			drive-strength = <8>;
			bias-disable;
		};

		data0-pins {
			pins = "gpio123";
			function = "i2s0_data0";
			drive-strength = <8>;
			bias-disable;
		};

		data1-pins {
			pins = "gpio124";
			function = "i2s0_data1";
			drive-strength = <8>;
			bias-disable;
		};
	};

	pcie0_default_state: pcie0-default-state {
		perst-n-pins {
			pins = "gpio102";
			function = "gpio";
			drive-strength = <2>;
			bias-disable;
		};

		clkreq-n-pins {
			pins = "gpio103";
			function = "pcie0_clk_req_n";
			drive-strength = <2>;
			bias-pull-up;
		};

		wake-n-pins {
			pins = "gpio104";
			function = "gpio";
			drive-strength = <2>;
			bias-pull-up;
		};
	};
};

&pmh0104_j_e1_gpios {
	bt_default: bt-default-state {
		pins = "gpio5";
		function = "normal";
		input-disable;
		output-enable;
		output-low;
		bias-disable;
		power-source = <1>;
	};
};

&lpass_vamacro {
	vdd-micb-supply = <&vreg_l10b_1p8>;
	qcom,dmic-sample-rate = <4800000>;
};

/*
&uart18 {
	status = "okay";

	/delete-property/ interrupts;

	interrupts-extended = <&intc GIC_SPI 587 IRQ_TYPE_LEVEL_HIGH 0>,
			      <&tlmm 27 IRQ_TYPE_EDGE_FALLING>;

	bluetooth {
		compatible = "qcom,wcn7850-bt";
		//max-speed = <3200000>;

		vddrfacmn-supply = <&vreg_pmu_rfa_cmn>;
		vddaon-supply = <&vreg_pmu_aon_0p59>;
		vddwlcx-supply = <&vreg_pmu_wlcx_0p8>;
		vddwlmx-supply = <&vreg_pmu_wlmx_0p85>;
		vddrfa0p8-supply = <&vreg_pmu_rfa_0p8>;
		vddrfa1p2-supply = <&vreg_pmu_rfa_1p2>;
		vddrfa1p8-supply = <&vreg_pmu_rfa_1p8>;
		qcom,local-bd-address-broken;

		//max-speed = <3200000>;
	};
};*/

&uart18 {
	status = "okay";

	/delete-property/ interrupts;

	interrupts-extended = <&intc GIC_SPI 587 IRQ_TYPE_LEVEL_HIGH 0>,
			      <&tlmm 27 IRQ_TYPE_EDGE_FALLING>;

	bluetooth {
		compatible = "qcom,wcn7860-bt";

		vddrfacmn-supply = <&vreg_pmu_rfa_cmn>;
		vddaon-supply = <&vreg_pmu_aon_0p59>;
		vddwlcx-supply = <&vreg_pmu_wlcx_0p8>;
		vddwlmx-supply = <&vreg_pmu_wlmx_0p85>;
		vddrfa0p8-supply = <&vreg_pmu_rfa_0p8>;
		vddrfa1p2-supply = <&vreg_pmu_rfa_1p2>;
		vddrfa1p8-supply = <&vreg_pmu_rfa_1p8>;

		max-speed = <3200000>;
	};
};

&ufs_mem_hc {
	reset-gpios = <&tlmm 217 GPIO_ACTIVE_LOW>;

	vcc-supply = <&vreg_l17b_2p5>;
	vcc-max-microamp = <1200000>;
	vccq-supply = <&vreg_l4d_1p2>;
	vccq-max-microamp = <1200000>;

	status = "okay";
};

&ufs_mem_phy {
	vdda-phy-supply = <&vreg_l4g_0p9>;
	vdda-pll-supply = <&vreg_l1d_1p2>;

	status = "okay";
};

&usb {
	status = "okay";
};

&usb_hsphy {
	vdd-supply = <&vreg_l4f_0p8>;
	vdda12-supply = <&vreg_l1d_1p2>;

	phys = <&pmih0108_e1_eusb2_repeater>;

	status = "okay";
};

&usb_dp_qmpphy {
	vdda-phy-supply = <&vreg_l4f_0p8>;
	vdda-pll-supply = <&vreg_l1d_1p2>;

	status = "okay";
};

&usb_dp_qmpphy_out {
	remote-endpoint = <&pmic_glink_ss_in>;
};

&usb_dwc3_hs {
	remote-endpoint = <&pmic_glink_hs_in>;
};
